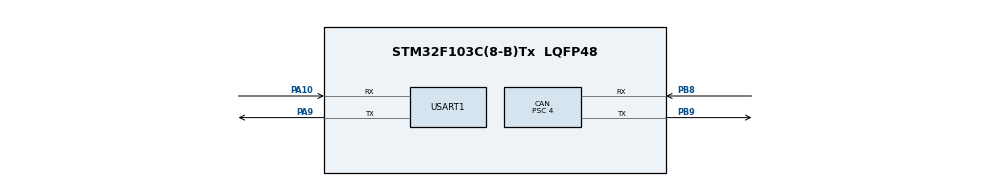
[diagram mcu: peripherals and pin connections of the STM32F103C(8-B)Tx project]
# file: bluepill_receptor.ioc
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CAN.BS1=CAN_BS1_13TQ
CAN.BS2=CAN_BS2_2TQ
CAN.CalculateBaudRate=125000
CAN.CalculateTimeBit=8000
CAN.CalculateTimeQuantum=500.0
CAN.Prescaler=4
FREERTOS.Tasks01=defaultTask,0,128,StartDefaultTask,Default,NULL,Dynamic,NULL,NULL
Mcu.Family=STM32F1
Mcu.Name=STM32F103C(8-B)Tx
Mcu.Package=LQFP48
NVIC.PriorityGroup=NVIC_PRIORITYGROUP_4
NVIC.TIM1_UP_IRQn=true\:15\:0\:false\:false\:true\:false\:false\:true\:true
NVIC.TimeBase=TIM1_UP_IRQn
NVIC.TimeBaseIP=TIM1
NVIC.USB_HP_CAN1_TX_IRQn=true\:5\:0\:false\:false\:true\:true\:true\:true\:true
NVIC.USB_LP_CAN1_RX0_IRQn=true\:5\:0\:false\:false\:true\:true\:true\:true\:true
PA10.Mode=Asynchronous
PA10.Signal=USART1_RX
PA13.Mode=Serial_Wire
PA13.Signal=SYS_JTMS-SWDIO
PA14.Mode=Serial_Wire
PA14.Signal=SYS_JTCK-SWCLK
PA9.Mode=Asynchronous
PA9.Signal=USART1_TX
PB8.GPIO_PuPd=GPIO_PULLUP
PB8.Mode=CAN_Activate
PB8.Signal=CAN_RX
PB9.Mode=CAN_Activate
PB9.Signal=CAN_TX
ProjectManager.HeapSize=0x200
ProjectManager.StackSize=0x400
ProjectManager.TargetToolchain=Makefile
RCC.APB1Freq_Value=8000000
RCC.APB2Freq_Value=8000000
USART1.VirtualMode=VM_ASYNC
VP_FREERTOS_VS_CMSIS_V1.Mode=CMSIS_V1
VP_SYS_VS_tim1.Mode=TIM1
board=custom

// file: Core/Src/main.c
 /* USER CODE BEGIN Header */

/**

******************************************************************************

* @file : main.c

* @brief : Main program body

******************************************************************************

* @attention

*

* Copyright (c) 2026 STMicroelectronics.

* All rights reserved.

*

* This software is licensed under terms that can be found in the LICENSE file

* in the root directory of this software component.

* If no LICENSE file comes with this software, it is provided AS-IS.

*

******************************************************************************

*/

/* USER CODE END Header */

#include "main.h"

#include "cmsis_os.h"

#include "can.h"
#include "can_app.h"

#include "usart.h"

#include "gpio.h"
#include <stdio.h>
#include <string.h>

/* USER CODE BEGIN PV */

extern CAN_HandleTypeDef hcan;
extern QueueHandle_t canRxQueue;

/* USER CODE END PV */

void SystemClock_Config(void);

void MX_FREERTOS_Init(void);

void CAN_Filter_Init(void);

/* USER CODE BEGIN PFP */

/* Función de procesamiento de recepción */

void HAL_CAN_RxFifo0MsgPendingCallback(CAN_HandleTypeDef *hcan)

{

printf(">> INT CAN <<\r\n");

CAN_Message_t msg;

BaseType_t xHigherPriorityTaskWoken = pdFALSE;

if (HAL_CAN_GetRxMessage(hcan, CAN_RX_FIFO0, &msg.header, msg.data) == HAL_OK)

{

xQueueSendFromISR(canRxQueue, &msg, &xHigherPriorityTaskWoken);

}

portYIELD_FROM_ISR(xHigherPriorityTaskWoken);

}

/* USER CODE END PFP */

int main(void)
{
  /* 1. Inicialización básica del sistema */
  HAL_Init();
  SystemClock_Config(); // Configurado a 32MHz para sincronizar con el emisor

  /* 2. Reloj de AFIO para el remap de pines PB8/PB9 */
  __HAL_RCC_AFIO_CLK_ENABLE();

  /* 3. Inicialización de periféricos de hardware */
  MX_GPIO_Init();
  MX_USART1_UART_Init();

  /* Imprimimos el inicio una vez que la UART está lista */
  printf("\r\n=== RECEPTOR MANTENIMIENTO PREDICTIVO ===\r\n");

  /* 4. Configuración del CAN (Debe estar en CAN_MODE_NORMAL en can.c) */
  MX_CAN_Init();
  CAN_Filter_Init(); // Filtro abierto para recibir RMS, PEAK, etc.

  /* 5. Inicializar objetos de FreeRTOS (Crea la cola canRxQueue) */
  /* Es vital que esto ocurra ANTES de activar las interrupciones del CAN */
  MX_FREERTOS_Init();

  /* 6. Arrancar el periférico CAN y activar notificaciones */
  if (HAL_CAN_Start(&hcan) == HAL_OK)
  {
      printf("CAN Iniciado correctamente en Modo Normal\r\n");

      /* Activamos la interrupción de recepción para el FIFO 0 */
      HAL_CAN_ActivateNotification(&hcan, CAN_IT_RX_FIFO0_MSG_PENDING | CAN_IT_ERROR);

      uint32_t state = HAL_CAN_GetState(&hcan);
      printf("Estado inicial del bus: %ld\r\n", state);
  }
  else
  {
      printf("Error crítico: No se pudo arrancar el CAN\r\n");
      Error_Handler();
  }

  /* 7. Iniciar el Scheduler de FreeRTOS */
  /* A partir de aquí, la tarea CAN_Rx_Task tomará el control de los datos */
  osKernelStart();

  /* El sistema no debería llegar nunca a este punto */
  while (1);
}

/* La función del filtro se mantiene igual, está perfecta */

void CAN_Filter_Init(void)

{

CAN_FilterTypeDef filter;

filter.FilterBank = 0; // Usamos el banco 0

filter.FilterMode = CAN_FILTERMODE_IDMASK;

filter.FilterScale = CAN_FILTERSCALE_32BIT;

filter.FilterIdHigh = 0x0000;

filter.FilterIdLow = 0x0000;

filter.FilterMaskIdHigh = 0x0000;

filter.FilterMaskIdLow = 0x0000; // Máscara en 0 deja pasar TODO

filter.FilterFIFOAssignment = CAN_FILTER_FIFO0;

filter.FilterActivation = ENABLE;

filter.SlaveStartFilterBank = 14;

if (HAL_CAN_ConfigFilter(&hcan, &filter) != HAL_OK)

{

printf("Error configurando filtro en main\r\n");

}

}

/* El _write para printf se mantiene igual al final */

/* UART printf support */

int _write(int file, char *ptr, int len)

{

HAL_UART_Transmit(&huart1, (uint8_t*)ptr, len, HAL_MAX_DELAY);

return len;

}

void SystemClock_Config(void)

{

RCC_OscInitTypeDef RCC_OscInitStruct = {0};

RCC_ClkInitTypeDef RCC_ClkInitStruct = {0};

RCC_OscInitStruct.OscillatorType = RCC_OSCILLATORTYPE_HSE;

RCC_OscInitStruct.HSEState = RCC_HSE_ON;

RCC_OscInitStruct.HSEPredivValue = RCC_HSE_PREDIV_DIV1;

RCC_OscInitStruct.PLL.PLLState = RCC_PLL_ON;

RCC_OscInitStruct.PLL.PLLSource = RCC_PLLSOURCE_HSE;

RCC_OscInitStruct.PLL.PLLMUL = RCC_PLL_MUL4; // 8MHz * 4 = 32MHz (Igual que el emisor)

if (HAL_RCC_OscConfig(&RCC_OscInitStruct) != HAL_OK)

{

Error_Handler();

}

RCC_ClkInitStruct.ClockType = RCC_CLOCKTYPE_HCLK|RCC_CLOCKTYPE_SYSCLK

|RCC_CLOCKTYPE_PCLK1|RCC_CLOCKTYPE_PCLK2;

RCC_ClkInitStruct.SYSCLKSource = RCC_SYSCLKSOURCE_PLLCLK;

RCC_ClkInitStruct.AHBCLKDivider = RCC_SYSCLK_DIV1;

RCC_ClkInitStruct.APB1CLKDivider = RCC_HCLK_DIV1; // APB1 a 32MHz

RCC_ClkInitStruct.APB2CLKDivider = RCC_HCLK_DIV1;

if (HAL_RCC_ClockConfig(&RCC_ClkInitStruct, FLASH_LATENCY_1) != HAL_OK)

{

Error_Handler();

}

}

void HAL_TIM_PeriodElapsedCallback(TIM_HandleTypeDef *htim)

{

if (htim->Instance == TIM1)

{

HAL_IncTick();

}

}

void Error_Handler(void)

{

__disable_irq();
while (1)
{
}

}

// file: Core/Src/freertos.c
 /* USER CODE BEGIN Header */

/**

******************************************************************************

* File Name : freertos.c

* Description : Code for freertos applications

******************************************************************************

* @attention

*

* Copyright (c) 2026 STMicroelectronics.

* All rights reserved.

*

* This software is licensed under terms that can be found in the LICENSE file

* in the root directory of this software component.

* If no LICENSE file comes with this software, it is provided AS-IS.

*

******************************************************************************

*/

/* USER CODE END Header */

#include "FreeRTOS.h"

#include "task.h"

#include "main.h"

#include "cmsis_os.h"
#include <stdio.h>    // Para printf
#include <string.h>   // Para memcpy
#include "can.h"      // Para que reconozca 'hcan'
#include "can_app.h"  // Para CAN_Message_t y CAN_Rx_Task

osThreadId acquireHandle;

osThreadId packageHandle;

osThreadId txCANHandle;

osMessageQId rawQueueHandle;

osMessageQId canQueueHandle;

QueueHandle_t rawQueue;

QueueHandle_t canQueue;

QueueHandle_t canRxQueue;

void StartTxCAN(void const * argument);

void MX_FREERTOS_Init(void); /* (MISRA C 2004 rule 8.1) */

/* GetIdleTaskMemory prototype (linked to static allocation support) */

void vApplicationGetIdleTaskMemory( StaticTask_t **ppxIdleTaskTCBBuffer, StackType_t **ppxIdleTaskStackBuffer, uint32_t *pulIdleTaskStackSize );

/* USER CODE BEGIN GET_IDLE_TASK_MEMORY */

static StaticTask_t xIdleTaskTCBBuffer;

static StackType_t xIdleStack[configMINIMAL_STACK_SIZE];

void vApplicationGetIdleTaskMemory( StaticTask_t **ppxIdleTaskTCBBuffer, StackType_t **ppxIdleTaskStackBuffer, uint32_t *pulIdleTaskStackSize )

{

*ppxIdleTaskTCBBuffer = &xIdleTaskTCBBuffer;

*ppxIdleTaskStackBuffer = &xIdleStack[0];

*pulIdleTaskStackSize = configMINIMAL_STACK_SIZE;

/* place for user code */

}

/* USER CODE END GET_IDLE_TASK_MEMORY */

void MX_FREERTOS_Init(void) {

/* USER CODE BEGIN RTOS_QUEUES */

canRxQueue = xQueueCreate(16, sizeof(CAN_Message_t));

/* USER CODE END RTOS_QUEUES */

/* Create the thread(s) */

/* definition and creation of defaultTask */

// osThreadDef(defaultTask, StartDefaultTask, osPriorityNormal, 0, 128);

// defaultTaskHandle = osThreadCreate(osThread(defaultTask), NULL);

/* USER CODE BEGIN RTOS_THREADS */

xTaskCreate(

CAN_Rx_Task,

"CAN_RX",

512,

NULL,

osPriorityNormal,

NULL

); /* USER CODE END RTOS_THREADS */

}

void CAN_Rx_Task(void *argument)
{
    CAN_Message_t msg;
    float value;

    for (;;)
    {
        //uint32_t esr = CAN1->ESR;
        //printf("ESR: 0x%08lX\r\n", esr);

        // 1. Monitoreo constante de errores de hardware
        uint32_t can_error = HAL_CAN_GetError(&hcan);
        if (can_error != HAL_CAN_ERROR_NONE) {
            // Si el error es 0x04, es falta de ACK (problema de cables o resistencias)
            // Si el error es 0x01, es Stuff Error (desincronización de baudrate)
            printf("!!! Error de Bus detectado: 0x%08lX\r\n", can_error);
        }

        // 2. Espera de mensajes en la cola
        if (xQueueReceive(canRxQueue, &msg, portMAX_DELAY) == pdTRUE)
        {
            // Si entra aquí, la comunicación física existe
            memcpy(&value, msg.data, sizeof(float));

            const char *label = "DESCONOCIDO";
            if (msg.header.StdId == 0x101) label = "RMS";
            else if (msg.header.StdId == 0x102) label = "CREST";
            else if (msg.header.StdId == 0x103) label = "PEAK";
            else if (msg.header.StdId == 0x104) label = "TEMP";

            printf(">> [RX] %s (ID: 0x%03lX) -> Val: %.3f\r\n",
                   label, msg.header.StdId, value);
        }
    }
}
